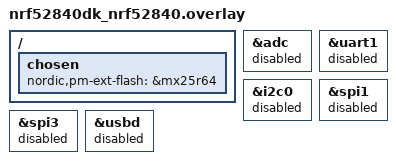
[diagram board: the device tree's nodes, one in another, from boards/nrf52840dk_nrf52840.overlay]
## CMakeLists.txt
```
#
# Copyright (c) 2024 Nordic Semiconductor ASA
#
# SPDX-License-Identifier: LicenseRef-Nordic-5-Clause
#

cmake_minimum_required(VERSION 3.20.0)

find_package(Zephyr HINTS $ENV{ZEPHYR_BASE})

project(matter-smoke-co-alarm)

# Enable GNU STD support.
include(${ZEPHYR_CONNECTEDHOMEIP_MODULE_DIR}/config/nrfconnect/app/enable-gnu-std.cmake)

# NORDIC SDK APP START

# Include all source files that are located in the Matter common directory.
include(${ZEPHYR_NRF_MODULE_DIR}/samples/matter/common/cmake/source_common.cmake)

# Include Data Model utils
include(${ZEPHYR_NRF_MODULE_DIR}/samples/matter/common/cmake/data_model.cmake)

include(${ZEPHYR_NRF_MODULE_DIR}/samples/matter/common/cmake/zap_helpers.cmake)
ncs_get_zap_parent_dir(ZAP_PARENT_DIR)

target_include_directories(app PRIVATE
    src
    ${ZAP_PARENT_DIR}
)

target_sources(app PRIVATE
    src/app_task.cpp
    src/main.cpp
    src/zcl_callbacks.cpp
)

ncs_configure_data_model()
# NORDIC SDK APP END
```

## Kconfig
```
#
# Copyright (c) 2024 Nordic Semiconductor
#
# SPDX-License-Identifier: LicenseRef-Nordic-5-Clause
#
mainmenu "Matter nRF Connect Smoke CO Alarm Example Application"

choice OPENTHREAD_NORDIC_LIBRARY_CONFIGURATION
	default OPENTHREAD_NORDIC_LIBRARY_MTD
endchoice

choice OPENTHREAD_DEVICE_TYPE
	default OPENTHREAD_MTD
endchoice

config CHIP_ENABLE_ICD_SUPPORT
	default y

config CHIP_ICD_LIT_SUPPORT
	default y

config CHIP_ICD_SIT_SLOW_POLL_LIMIT
	default 5000

config CHIP_ICD_REPORT_ON_ACTIVE_MODE
	default y

# Increase the supported event triggers due to the multiple alarm triggers
config NCS_SAMPLE_MATTER_TEST_EVENT_TRIGGERS_MAX
	default 12

# Reduce Thread TX output power to 0 dBm for SED device
config OPENTHREAD_DEFAULT_TX_POWER
	default 0

source "${ZEPHYR_CONNECTEDHOMEIP_MODULE_DIR}/config/nrfconnect/chip-module/Kconfig.features"
source "${ZEPHYR_CONNECTEDHOMEIP_MODULE_DIR}/config/nrfconnect/chip-module/Kconfig.defaults"
source "${ZEPHYR_NRF_MODULE_DIR}/samples/matter/common/src/Kconfig"
source "Kconfig.zephyr"
```

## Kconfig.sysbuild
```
#
# Copyright (c) 2024 Nordic Semiconductor ASA
#
# SPDX-License-Identifier: LicenseRef-Nordic-5-Clause
#

#### Radio core selection
config NRF_DEFAULT_IPC_RADIO
	default y

# Enable IEEE802.15.4 serialization to network core
# This config automatically pulls in the `overlay-802154.conf` in the ipc_radio image
config NETCORE_IPC_RADIO_IEEE802154
	default y if SOC_SERIES_NRF53X

# Enable Bluetooth serialization to network core
# This config automatically pulls in the `overlay-bt_hci_ipc.conf` in the ipc_radio image
config NETCORE_IPC_RADIO_BT_HCI_IPC
	default y if SOC_SERIES_NRF53X

#### Bootloader
choice BOOTLOADER
	default BOOTLOADER_MCUBOOT
endchoice

if BOOTLOADER_MCUBOOT

#### DFU multi-image support
config DFU_MULTI_IMAGE_PACKAGE_BUILD
	default y

config DFU_MULTI_IMAGE_PACKAGE_APP
	default y

config PM_EXTERNAL_FLASH_MCUBOOT_SECONDARY
	default y

#### DFU network core configuration
if SOC_SERIES_NRF53X

config MCUBOOT_UPDATEABLE_IMAGES
	default 2

choice MCUBOOT_MODE
	default MCUBOOT_MODE_OVERWRITE_ONLY
endchoice

choice BOOT_SIGNATURE_TYPE
	default BOOT_SIGNATURE_TYPE_RSA
endchoice

config SECURE_BOOT_NETCORE
	default y

config NETCORE_APP_UPDATE
	default y

config DFU_MULTI_IMAGE_PACKAGE_NET
	default y

endif # SOC_SERIES_NRF53X

if BOARD_NRF54L15DK

# Disable checking the external drivers for nRF54L15 DKs.
config PM_OVERRIDE_EXTERNAL_DRIVER_CHECK
	default y

endif # BOARD_NRF54L15DK

# Mcuboot padding size is modified to 0x1000 in pm_static file.
if SOC_NRF54L10

config PM_MCUBOOT_PAD
	default 0x1000

endif # SOC_NRF54L10

endif # BOOTLOADER_MCUBOOT

#### Enable generating factory data
config MATTER_FACTORY_DATA_GENERATE
	default y

source "share/sysbuild/Kconfig"
```

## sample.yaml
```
sample:
  description: Matter Smoke CO Alarm example
  name: Matter Smoke CO Alarm
tests:
  sample.matter.smoke_co_alarm.debug:
    sysbuild: true
    build_only: true
    integration_platforms:
      - nrf52840dk/nrf52840
      - nrf5340dk/nrf5340/cpuapp
      - nrf54l15dk/nrf54l15/cpuapp
      - nrf54l15dk/nrf54l10/cpuapp
      - nrf54lm20pdk/nrf54lm20a/cpuapp
    platform_allow:
      - nrf52840dk/nrf52840
      - nrf5340dk/nrf5340/cpuapp
      - nrf54l15dk/nrf54l15/cpuapp
      - nrf54l15dk/nrf54l10/cpuapp
      - nrf54lm20pdk/nrf54lm20a/cpuapp
    tags:
      - sysbuild
      - ci_samples_matter
  sample.matter.smoke_co_alarm.release:
    sysbuild: true
    build_only: true
    extra_args:
      - FILE_SUFFIX=release
      - SB_CONFIG_BOOTLOADER_MCUBOOT=y
      - SB_CONFIG_PARTITION_MANAGER=y
    integration_platforms:
      - nrf52840dk/nrf52840
      - nrf5340dk/nrf5340/cpuapp
      - nrf54l15dk/nrf54l15/cpuapp
      - nrf54l15dk/nrf54l10/cpuapp
      - nrf54lm20pdk/nrf54lm20a/cpuapp
    platform_allow:
      - nrf52840dk/nrf52840
      - nrf5340dk/nrf5340/cpuapp
      - nrf54l15dk/nrf54l15/cpuapp
      - nrf54l15dk/nrf54l10/cpuapp
      - nrf54lm20pdk/nrf54lm20a/cpuapp
    tags:
      - sysbuild
      - ci_samples_matter
  sample.matter.smoke_co_alarm.release.power_consumption:
    sysbuild: true
    build_only: true
    extra_args:
      - FILE_SUFFIX=release
      - smoke_co_alarm_SNIPPET=power-consumption-tests
    integration_platforms:
      - nrf52840dk/nrf52840
      - nrf5340dk/nrf5340/cpuapp
      - nrf54l15dk/nrf54l15/cpuapp
      - nrf54lm20pdk/nrf54lm20a/cpuapp
    platform_allow:
      - nrf52840dk/nrf52840
      - nrf5340dk/nrf5340/cpuapp
      - nrf54l15dk/nrf54l15/cpuapp
      - nrf54lm20pdk/nrf54lm20a/cpuapp
    tags:
      - sysbuild
      - ci_samples_matter
  sample.matter.smoke_co_alarm.debug.reference:
    sysbuild: true
    build_only: true
    integration_platforms:
      - nrf54l15dk/nrf54l15/cpuapp
    extra_args:
      - smoke_co_alarm_SNIPPET="diagnostic-logs"
    platform_allow: nrf54l15dk/nrf54l15/cpuapp
    tags:
      - sysbuild
      - ci_samples_matter
```

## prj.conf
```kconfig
#
# Copyright (c) 2024 Nordic Semiconductor ASA
#
# SPDX-License-Identifier: LicenseRef-Nordic-5-Clause
#

# Enable CHIP
CONFIG_CHIP=y
CONFIG_CHIP_PROJECT_CONFIG="src/chip_project_config.h"

# Configure ZAP file name
CONFIG_NCS_SAMPLE_MATTER_ZAP_FILE_PATH="${APPLICATION_CONFIG_DIR}/src/default_zap/smoke_co_alarm.zap"

# 32768 == 0x8000 (example Product ID added temporaly,
# as there is no assigned PID on the following list:
# https://github.com/project-chip/connectedhomeip/blob/482e6fd03196a6de45465a90003947ef4b86e0b1/docs/examples/discussion/PID_allocation_for_example_apps.md)
CONFIG_CHIP_DEVICE_PRODUCT_ID=32768
CONFIG_STD_CPP17=y

# Enable Matter pairing automatically on application start.
CONFIG_CHIP_ENABLE_PAIRING_AUTOSTART=y

# Enable Matter extended announcement and increase duration to 1 hour.
CONFIG_CHIP_BLE_EXT_ADVERTISING=y
CONFIG_CHIP_BLE_ADVERTISING_DURATION=60

# Add support for LEDs and buttons on Nordic development kits
CONFIG_DK_LIBRARY=y

# Bluetooth Low Energy configuration
CONFIG_BT_DEVICE_NAME="MatterSmoke"

# Suspend devices when the CPU goes into sleep
CONFIG_PM_DEVICE=y

# Other settings
CONFIG_THREAD_NAME=y
CONFIG_MPU_STACK_GUARD=y
CONFIG_RESET_ON_FATAL_ERROR=n
CONFIG_CHIP_LIB_SHELL=y

# Reduce application size
CONFIG_USE_SEGGER_RTT=n

# Enable Factory Data feature
CONFIG_CHIP_FACTORY_DATA=y
CONFIG_CHIP_FACTORY_DATA_BUILD=y
```

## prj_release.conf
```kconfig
#
# Copyright (c) 2024 Nordic Semiconductor ASA
#
# SPDX-License-Identifier: LicenseRef-Nordic-5-Clause
#

# Enable CHIP
CONFIG_CHIP=y
CONFIG_CHIP_PROJECT_CONFIG="src/chip_project_config.h"

# Configure ZAP file name
CONFIG_NCS_SAMPLE_MATTER_ZAP_FILE_PATH="${APPLICATION_CONFIG_DIR}/src/default_zap/smoke_co_alarm.zap"

# 32768 == 0x8000 (example Product ID added temporaly,
# as there is no assigned PID on the following list:
# https://github.com/project-chip/connectedhomeip/blob/482e6fd03196a6de45465a90003947ef4b86e0b1/docs/examples/discussion/PID_allocation_for_example_apps.md)
CONFIG_CHIP_DEVICE_PRODUCT_ID=32768
CONFIG_STD_CPP17=y

# Enable Matter pairing automatically on application start.
CONFIG_CHIP_ENABLE_PAIRING_AUTOSTART=y

# Enable Matter extended announcement and increase duration to 1 hour.
CONFIG_CHIP_BLE_EXT_ADVERTISING=y
CONFIG_CHIP_BLE_ADVERTISING_DURATION=60

# Add support for LEDs and buttons on Nordic development kits
CONFIG_DK_LIBRARY=y

# Try to disable unused RAM blocks to reduce power consumption
CONFIG_RAM_POWER_DOWN_LIBRARY=y

# Bluetooth Low Energy configuration
CONFIG_BT_DEVICE_NAME="MatterSmoke"

# Suspend devices when the CPU goes into sleep
CONFIG_PM_DEVICE=y

# Enable system reset on fatal error
CONFIG_RESET_ON_FATAL_ERROR=y

# Disable all debug features
CONFIG_USE_SEGGER_RTT=n
CONFIG_SHELL=n
CONFIG_OPENTHREAD_SHELL=n
CONFIG_CONSOLE=n
CONFIG_UART_CONSOLE=n
CONFIG_SERIAL=n
CONFIG_LOG=n
CONFIG_LOG_MODE_MINIMAL=n
CONFIG_ASSERT_VERBOSE=n
CONFIG_ASSERT_NO_FILE_INFO=y
CONFIG_PRINTK=n
CONFIG_PRINTK_SYNC=n
CONFIG_THREAD_NAME=n
CONFIG_BOOT_BANNER=n

# Enable Factory Data feature
CONFIG_CHIP_FACTORY_DATA=y
CONFIG_CHIP_FACTORY_DATA_BUILD=y

# Enable Watchdog
CONFIG_NCS_SAMPLE_MATTER_WATCHDOG=y

# Enable LTO to decrease the flash usage.
CONFIG_LTO=y
CONFIG_ISR_TABLES_LOCAL_DECLARATION=y
```

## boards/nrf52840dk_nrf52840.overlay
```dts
/*
 * Copyright (c) 2024 Nordic Semiconductor ASA
 *
 * SPDX-License-Identifier: LicenseRef-Nordic-5-Clause
 */

/ {
	chosen {
		nordic,pm-ext-flash = &mx25r64;
	};
};

/* Disable unused peripherals to reduce power consumption */
&adc {
	status = "disabled";
};
&uart1 {
	status = "disabled";
};
&i2c0 {
	status = "disabled";
};
&spi1 {
	status = "disabled";
};
&spi3 {
	status = "disabled";
};
&usbd {
	status = "disabled";
};
```

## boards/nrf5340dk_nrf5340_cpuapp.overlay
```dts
/*
 * Copyright (c) 2024 Nordic Semiconductor ASA
 *
 * SPDX-License-Identifier: LicenseRef-Nordic-5-Clause
 */

#include <zephyr/dt-bindings/ipc_service/static_vrings.h>

/ {
	chosen {
		nordic,pm-ext-flash = &mx25r64;
	};
};

/* Set IPC thread priority to the highest value to not collide with other threads. */
&ipc0 {
	zephyr,priority = <0 PRIO_COOP>;
};

/* Disable unused peripherals to reduce power consumption */
&adc {
	status = "disabled";
};
&i2c1 {
	status = "disabled";
};
&spi2 {
	status = "disabled";
};
&usbd {
	status = "disabled";
};
```

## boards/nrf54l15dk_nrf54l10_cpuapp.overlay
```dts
/*
 * Copyright (c) 2024 Nordic Semiconductor ASA
 *
 * SPDX-License-Identifier: LicenseRef-Nordic-5-Clause
 */


/ {
	chosen {
		nordic,pm-ext-flash = &mx25r64;
	};

	aliases {
		// Use watchdog wdt31 as the application watchdog
		watchdog0 = &wdt31;
	};
};

// restore full RRAM and SRAM space - by default some parts are dedicated to FLRP
&cpuapp_rram {
	reg = <0x0 DT_SIZE_K(1022)>;
};

&cpuapp_sram {
	reg = <0x20000000 DT_SIZE_K(192)>;
	ranges = <0x0 0x20000000  DT_SIZE_K(192)>;
};

// TODO: re-enable HWFC once it's fixed
&uart20 {
	/delete-property/ hw-flow-control;
};

&mx25r64 {
	status = "okay";
};

&wdt31 {
	status = "okay";
};
```

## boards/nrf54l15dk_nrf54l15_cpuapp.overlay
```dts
/*
 * Copyright (c) 2024 Nordic Semiconductor ASA
 *
 * SPDX-License-Identifier: LicenseRef-Nordic-5-Clause
 */


/ {
	chosen {
		nordic,pm-ext-flash = &mx25r64;
	};

	aliases {
		// Use watchdog wdt31 as the application watchdog
		watchdog0 = &wdt31;
	};
};

// restore full RRAM and SRAM space - by default some parts are dedicated to FLRP
&cpuapp_rram {
	reg = <0x0 DT_SIZE_K(1524)>;
};

&cpuapp_sram {
	reg = <0x20000000 DT_SIZE_K(256)>;
	ranges = <0x0 0x20000000  0x40000>;
};

// TODO: re-enable HWFC once it's fixed
&uart20 {
	/delete-property/ hw-flow-control;
};

&mx25r64 {
	status = "okay";
};

&wdt31 {
	status = "okay";
};
```

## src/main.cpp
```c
/*
 * Copyright (c) 2024 Nordic Semiconductor ASA
 *
 * SPDX-License-Identifier: LicenseRef-Nordic-5-Clause
 */

#include "app_task.h"

#include <zephyr/logging/log.h>

LOG_MODULE_REGISTER(app, CONFIG_CHIP_APP_LOG_LEVEL);

int main()
{
	CHIP_ERROR err = AppTask::Instance().StartApp();

	LOG_ERR("Exited with code %" CHIP_ERROR_FORMAT, err.Format());
	return err == CHIP_NO_ERROR ? EXIT_SUCCESS : EXIT_FAILURE;
}
```

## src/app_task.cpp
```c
/*
 * Copyright (c) 2024 Nordic Semiconductor ASA
 *
 * SPDX-License-Identifier: LicenseRef-Nordic-5-Clause
 */

#include "app_task.h"

#include "app/matter_init.h"
#include "app/task_executor.h"
#include "board/board.h"
#include "lib/core/CHIPError.h"
#include "lib/support/CodeUtils.h"

#include <app-common/zap-generated/attributes/Accessors.h>
#include <app/clusters/identify-server/identify-server.h>
#include <app/clusters/smoke-co-alarm-server/SmokeCOTestEventTriggerHandler.h>
#include <app/clusters/smoke-co-alarm-server/smoke-co-alarm-server.h>
#include <setup_payload/OnboardingCodesUtil.h>

#include <zephyr/logging/log.h>

LOG_MODULE_DECLARE(app, CONFIG_CHIP_APP_LOG_LEVEL);

using namespace ::chip;
using namespace ::chip::app;
using namespace ::chip::DeviceLayer;

namespace
{

constexpr uint32_t kExpressedStateLedEvenBlinkMs = 300;
constexpr uint32_t kExpressedStateLedOddBlink1Ms = 300;
constexpr uint32_t kExpressedStateLedOddBlink2Ms = 700;
constexpr uint32_t kSelfTestDurationMs = 5000;
constexpr uint32_t kSelfTestLedUpdateTimeMs = 200;

static std::array<Clusters::SmokeCoAlarm::ExpressedStateEnum, SmokeCoAlarmServer::kPriorityOrderLength>
	sPriorityOrder = { Clusters::SmokeCoAlarm::ExpressedStateEnum::kSmokeAlarm,
			   Clusters::SmokeCoAlarm::ExpressedStateEnum::kCOAlarm,
			   Clusters::SmokeCoAlarm::ExpressedStateEnum::kHardwareFault,
			   Clusters::SmokeCoAlarm::ExpressedStateEnum::kTesting,
			   Clusters::SmokeCoAlarm::ExpressedStateEnum::kEndOfService,
			   Clusters::SmokeCoAlarm::ExpressedStateEnum::kBatteryAlert,
			   Clusters::SmokeCoAlarm::ExpressedStateEnum::kInterconnectSmoke,
			   Clusters::SmokeCoAlarm::ExpressedStateEnum::kInterconnectCO };

Identify sIdentify = { AppTask::Instance().kSmokeCoAlarmEndpointId, AppTask::IdentifyStartHandler,
		       AppTask::IdentifyStopHandler, Clusters::Identify::IdentifyTypeEnum::kVisibleIndicator };

#ifdef CONFIG_CHIP_ICD_UAT_SUPPORT
#define UAT_BUTTON_MASK DK_BTN3_MSK
#endif
} /* namespace */

void AppTask::IdentifyStartHandler(Identify *)
{
	Nrf::PostTask(
		[] { Nrf::GetBoard().GetLED(Nrf::DeviceLeds::LED2).Blink(Nrf::LedConsts::kIdentifyBlinkRate_ms); });
}

void AppTask::IdentifyStopHandler(Identify *)
{
	Nrf::PostTask([] { Nrf::GetBoard().GetLED(Nrf::DeviceLeds::LED2).Set(false); });
}

void AppTask::ButtonEventHandler(Nrf::ButtonState state, Nrf::ButtonMask hasChanged)
{
#ifdef CONFIG_CHIP_ICD_UAT_SUPPORT
	if ((UAT_BUTTON_MASK & state & hasChanged)) {
		LOG_INF("ICD UserActiveMode has been triggered.");
		Server::GetInstance().GetICDManager().OnNetworkActivity();
	}
#endif
}

void AppTask::UpdatedExpressedLedState()
{
	Clusters::SmokeCoAlarm::ExpressedStateEnum state;
	SmokeCoAlarmServer::Instance().GetExpressedState(kSmokeCoAlarmEndpointId, state);

	if (mCurrentState == state) {
		return;
	}
	mCurrentState = state;

	k_timer_stop(&mSelfTestLedTimer);

	switch (state) {
	case Clusters::SmokeCoAlarm::ExpressedStateEnum::kNormal:
		Nrf::GetBoard().GetLED(Nrf::DeviceLeds::LED2).Set(false);
		Nrf::GetBoard().GetLED(Nrf::DeviceLeds::LED3).Set(false);
		Nrf::GetBoard().GetLED(Nrf::DeviceLeds::LED4).Set(false);
		break;
	case Clusters::SmokeCoAlarm::ExpressedStateEnum::kSmokeAlarm:
		Nrf::GetBoard().GetLED(Nrf::DeviceLeds::LED2).Blink(kExpressedStateLedEvenBlinkMs);
		Nrf::GetBoard().GetLED(Nrf::DeviceLeds::LED3).Set(false);
		Nrf::GetBoard().GetLED(Nrf::DeviceLeds::LED4).Set(false);
		break;
	case Clusters::SmokeCoAlarm::ExpressedStateEnum::kCOAlarm:
		Nrf::GetBoard().GetLED(Nrf::DeviceLeds::LED2).Set(false);
		Nrf::GetBoard().GetLED(Nrf::DeviceLeds::LED3).Blink(kExpressedStateLedEvenBlinkMs);
		Nrf::GetBoard().GetLED(Nrf::DeviceLeds::LED4).Set(false);
		break;
	case Clusters::SmokeCoAlarm::ExpressedStateEnum::kBatteryAlert:
		Nrf::GetBoard().GetLED(Nrf::DeviceLeds::LED2).Set(false);
		Nrf::GetBoard().GetLED(Nrf::DeviceLeds::LED3).Set(false);
		Nrf::GetBoard().GetLED(Nrf::DeviceLeds::LED4).Blink(kExpressedStateLedEvenBlinkMs);
		break;
	case Clusters::SmokeCoAlarm::ExpressedStateEnum::kTesting:
		Nrf::GetBoard().GetLED(Nrf::DeviceLeds::LED2).Set(false);
		Nrf::GetBoard().GetLED(Nrf::DeviceLeds::LED3).Set(false);
		Nrf::GetBoard().GetLED(Nrf::DeviceLeds::LED4).Set(false);

		k_timer_start(&mSelfTestLedTimer, K_MSEC(kSelfTestLedUpdateTimeMs), K_NO_WAIT);
		Nrf::GetBoard().GetLED(Nrf::DeviceLeds::LED2).Set(true);

		break;
	case Clusters::SmokeCoAlarm::ExpressedStateEnum::kHardwareFault:
		Nrf::GetBoard().GetLED(Nrf::DeviceLeds::LED2).Set(false);
		Nrf::GetBoard().GetLED(Nrf::DeviceLeds::LED3).Set(false);
		Nrf::GetBoard().GetLED(Nrf::DeviceLeds::LED4).Set(false);

		Nrf::GetBoard()
			.GetLED(Nrf::DeviceLeds::LED2)
			.Blink(kExpressedStateLedOddBlink1Ms, kExpressedStateLedOddBlink2Ms);
		Nrf::GetBoard()
			.GetLED(Nrf::DeviceLeds::LED3)
			.Blink(kExpressedStateLedOddBlink1Ms, kExpressedStateLedOddBlink2Ms);
		Nrf::GetBoard()
			.GetLED(Nrf::DeviceLeds::LED4)
			.Blink(kExpressedStateLedOddBlink1Ms, kExpressedStateLedOddBlink2Ms);
		break;
	case Clusters::SmokeCoAlarm::ExpressedStateEnum::kEndOfService:
		Nrf::GetBoard().GetLED(Nrf::DeviceLeds::LED2).Set(false);
		Nrf::GetBoard().GetLED(Nrf::DeviceLeds::LED3).Set(false);
		Nrf::GetBoard().GetLED(Nrf::DeviceLeds::LED4).Set(false);

		Nrf::GetBoard()
			.GetLED(Nrf::DeviceLeds::LED2)
			.Blink(kExpressedStateLedOddBlink2Ms, kExpressedStateLedOddBlink1Ms);
		Nrf::GetBoard()
			.GetLED(Nrf::DeviceLeds::LED3)
			.Blink(kExpressedStateLedOddBlink2Ms, kExpressedStateLedOddBlink1Ms);
		Nrf::GetBoard()
			.GetLED(Nrf::DeviceLeds::LED4)
			.Blink(kExpressedStateLedOddBlink2Ms, kExpressedStateLedOddBlink1Ms);
		break;
	case Clusters::SmokeCoAlarm::ExpressedStateEnum::kInterconnectSmoke:
	case Clusters::SmokeCoAlarm::ExpressedStateEnum::kInterconnectCO:
	case Clusters::SmokeCoAlarm::ExpressedStateEnum::kUnknownEnumValue:
	default:
		break;
	}
}

bool HandleSmokeCOTestEventTrigger(uint64_t eventTrigger)
{
	SmokeCOTrigger trigger = static_cast<SmokeCOTrigger>(eventTrigger);

	switch (trigger) {
	case SmokeCOTrigger::kForceSmokeCritical:
		LOG_INF("Triggered smoke alarm with critical severity");
		VerifyOrReturnValue(
			SmokeCoAlarmServer::Instance().SetSmokeState(AppTask::Instance().kSmokeCoAlarmEndpointId,
								     Clusters::SmokeCoAlarm::AlarmStateEnum::kCritical),
			false);
		SmokeCoAlarmServer::Instance().SetExpressedStateByPriority(AppTask::Instance().kSmokeCoAlarmEndpointId,
									   sPriorityOrder);
		break;
	case SmokeCOTrigger::kForceCOCritical:
		LOG_INF("Triggered CO alarm with critical severity");
		VerifyOrReturnValue(
			SmokeCoAlarmServer::Instance().SetCOState(AppTask::Instance().kSmokeCoAlarmEndpointId,
								  Clusters::SmokeCoAlarm::AlarmStateEnum::kCritical),
			false);
		SmokeCoAlarmServer::Instance().SetExpressedStateByPriority(AppTask::Instance().kSmokeCoAlarmEndpointId,
									   sPriorityOrder);
		break;
	case SmokeCOTrigger::kForceMalfunction:
		LOG_INF("Triggered hardware fault alert");
		VerifyOrReturnValue(SmokeCoAlarmServer::Instance().SetHardwareFaultAlert(
					    AppTask::Instance().kSmokeCoAlarmEndpointId, true),
				    false);
		SmokeCoAlarmServer::Instance().SetExpressedStateByPriority(AppTask::Instance().kSmokeCoAlarmEndpointId,
									   sPriorityOrder);
		break;
	case SmokeCOTrigger::kForceLowBatteryCritical:
		LOG_INF("Triggered low battery alert with critical severity");
		VerifyOrReturnValue(SmokeCoAlarmServer::Instance().SetBatteryAlert(
					    AppTask::Instance().kSmokeCoAlarmEndpointId,
					    Clusters::SmokeCoAlarm::AlarmStateEnum::kCritical),
				    false);
		SmokeCoAlarmServer::Instance().SetExpressedStateByPriority(AppTask::Instance().kSmokeCoAlarmEndpointId,
									   sPriorityOrder);
		break;
	case SmokeCOTrigger::kForceEndOfLife:
		LOG_INF("Triggered end of service alert");
		VerifyOrReturnValue(SmokeCoAlarmServer::Instance().SetEndOfServiceAlert(
					    AppTask::Instance().kSmokeCoAlarmEndpointId,
					    Clusters::SmokeCoAlarm::EndOfServiceEnum::kExpired),
				    false);
		SmokeCoAlarmServer::Instance().SetExpressedStateByPriority(AppTask::Instance().kSmokeCoAlarmEndpointId,
									   sPriorityOrder);
		break;
	case SmokeCOTrigger::kClearSmoke:
		LOG_INF("Triggered end of smoke alarm action");
		VerifyOrReturnValue(
			SmokeCoAlarmServer::Instance().SetSmokeState(AppTask::Instance().kSmokeCoAlarmEndpointId,
								     Clusters::SmokeCoAlarm::AlarmStateEnum::kNormal),
			false);
		SmokeCoAlarmServer::Instance().SetExpressedStateByPriority(AppTask::Instance().kSmokeCoAlarmEndpointId,
									   sPriorityOrder);
		break;
	case SmokeCOTrigger::kClearCO:
		LOG_INF("Triggered end of CO alarm action");
		VerifyOrReturnValue(
			SmokeCoAlarmServer::Instance().SetCOState(AppTask::Instance().kSmokeCoAlarmEndpointId,
								  Clusters::SmokeCoAlarm::AlarmStateEnum::kNormal),
			false);
		SmokeCoAlarmServer::Instance().SetExpressedStateByPriority(AppTask::Instance().kSmokeCoAlarmEndpointId,
									   sPriorityOrder);
		break;
	case SmokeCOTrigger::kClearMalfunction:
		LOG_INF("Triggered end of hardware fault alert action");
		VerifyOrReturnValue(SmokeCoAlarmServer::Instance().SetHardwareFaultAlert(
					    AppTask::Instance().kSmokeCoAlarmEndpointId, false),
				    false);
		SmokeCoAlarmServer::Instance().SetExpressedStateByPriority(AppTask::Instance().kSmokeCoAlarmEndpointId,
									   sPriorityOrder);
		break;
	case SmokeCOTrigger::kClearEndOfLife:
		LOG_INF("Triggered end of end of service alert action");
		VerifyOrReturnValue(SmokeCoAlarmServer::Instance().SetEndOfServiceAlert(
					    AppTask::Instance().kSmokeCoAlarmEndpointId,
					    Clusters::SmokeCoAlarm::EndOfServiceEnum::kNormal),
				    false);
		SmokeCoAlarmServer::Instance().SetExpressedStateByPriority(AppTask::Instance().kSmokeCoAlarmEndpointId,
									   sPriorityOrder);
		break;
	case SmokeCOTrigger::kClearBatteryLevelLow:
		LOG_INF("Triggered end of low battery level alert action");
		VerifyOrReturnValue(
			SmokeCoAlarmServer::Instance().SetBatteryAlert(AppTask::Instance().kSmokeCoAlarmEndpointId,
								       Clusters::SmokeCoAlarm::AlarmStateEnum::kNormal),
			false);
		SmokeCoAlarmServer::Instance().SetExpressedStateByPriority(AppTask::Instance().kSmokeCoAlarmEndpointId,
									   sPriorityOrder);
		break;
	case SmokeCOTrigger::kForceSmokeWarning:
		LOG_WRN("Triggered unsupported smoke alarm with warning severity");
		return false;
	case SmokeCOTrigger::kForceSmokeInterconnect:
		LOG_WRN("Triggered unsupported smoke interconnect alarm");
		return false;
	case SmokeCOTrigger::kForceCOWarning:
		LOG_WRN("Triggered unsupported CO alarm with warning severity");
		return false;
	case SmokeCOTrigger::kForceCOInterconnect:
		LOG_WRN("Triggered unsupported CO interconnect alarm");
		return false;
	case SmokeCOTrigger::kForceSmokeContaminationHigh:
		LOG_WRN("Triggered unsupported high smoke contamination alarm");
		return false;
	case SmokeCOTrigger::kForceSmokeContaminationLow:
		LOG_WRN("Triggered unsupported low smoke contamination alarm");
		return false;
	case SmokeCOTrigger::kForceSmokeSensitivityHigh:
		LOG_WRN("Triggered unsupported high smoke sensitivity alarm");
		return false;
	case SmokeCOTrigger::kForceSmokeSensitivityLow:
		LOG_WRN("Triggered unsupported low smoke sensitivity alarm");
		return false;
	case SmokeCOTrigger::kForceLowBatteryWarning:
		LOG_WRN("Triggered unsupported low battery alert with warning severity");
		return false;
	case SmokeCOTrigger::kForceSilence:
		LOG_WRN("Triggered unsupported alarm mute action");
		return false;
	case SmokeCOTrigger::kClearSmokeInterconnect:
		LOG_WRN("Triggered unsupported end of smoke interconnect alarm action");
		return false;
	case SmokeCOTrigger::kClearCOInterconnect:
		LOG_WRN("Triggered unsupported end of CO interconnect alarm action");
		return false;
	case SmokeCOTrigger::kClearSilence:
		LOG_WRN("Triggered unsupported unmute action");
		return false;
	case SmokeCOTrigger::kClearContamination:
		LOG_WRN("Triggered unsupported end of smoke contamination alert action");
		return false;
	case SmokeCOTrigger::kClearSensitivity:
		LOG_WRN("Triggered unsupported end of smoke sensitivity alert action");
		return false;
	default:
		return false;
	}

	AppTask::Instance().UpdatedExpressedLedState();

	return true;
}

void AppTask::SelfTestTimerTimeoutCallback(k_timer *timer)
{
	Nrf::PostTask([] { EndSelfTestEventHandler(); });
}

void AppTask::EndSelfTestEventHandler()
{
	LOG_INF("Alarm self test action end");
	SmokeCoAlarmServer::Instance().SetTestInProgress(kSmokeCoAlarmEndpointId, false);
	SmokeCoAlarmServer::Instance().SetExpressedStateByPriority(kSmokeCoAlarmEndpointId, sPriorityOrder);
	Instance().UpdatedExpressedLedState();
}

void AppTask::SelfTestLedTimerTimeoutCallback(k_timer *timer)
{
	Nrf::PostTask([] { SelfTestLedTimerEventHandler(); });
}

void AppTask::SelfTestLedTimerEventHandler()
{
	if (Nrf::GetBoard().GetLED(Nrf::DeviceLeds::LED2).GetState()) {
		Nrf::GetBoard().GetLED(Nrf::DeviceLeds::LED2).Set(false);
		Nrf::GetBoard().GetLED(Nrf::DeviceLeds::LED3).Set(true);
	} else if (Nrf::GetBoard().GetLED(Nrf::DeviceLeds::LED3).GetState()) {
		Nrf::GetBoard().GetLED(Nrf::DeviceLeds::LED3).Set(false);
		Nrf::GetBoard().GetLED(Nrf::DeviceLeds::LED4).Set(true);
	} else if (Nrf::GetBoard().GetLED(Nrf::DeviceLeds::LED4).GetState()) {
		Nrf::GetBoard().GetLED(Nrf::DeviceLeds::LED4).Set(false);
		Nrf::GetBoard().GetLED(Nrf::DeviceLeds::LED2).Set(true);
	}

	k_timer_start(&Instance().mSelfTestLedTimer, K_MSEC(kSelfTestLedUpdateTimeMs), K_NO_WAIT);
}

#ifdef CONFIG_NCS_SAMPLE_MATTER_TEST_EVENT_TRIGGERS
CHIP_ERROR AppTask::PowerSourceOnEventCallback(Nrf::Matter::TestEventTrigger::TriggerValue endpointId)
{
	if (endpointId == kWiredPowerSourceEndpointId || endpointId == kBatteryPowerSourceEndpointId) {
		LOG_INF("Event Trigger: Power Source on endpoint id %d activated.", endpointId);
	} else {
		LOG_ERR("Event Trigger: Power Source On triggered on invalid endpoint id %d", endpointId);
		return CHIP_ERROR_INVALID_ARGUMENT;
	}

	/* Wired power source is treated as primary one. */
	if (endpointId == kWiredPowerSourceEndpointId) {
		Clusters::PowerSource::Attributes::Status::Set(kWiredPowerSourceEndpointId,
							       Clusters::PowerSource::PowerSourceStatusEnum::kActive);

		Clusters::PowerSource::PowerSourceStatusEnum status;
		Clusters::PowerSource::Attributes::Status::Get(kBatteryPowerSourceEndpointId, &status);

		/* If battery power source was active, change its state to standby. */
		if (status == Clusters::PowerSource::PowerSourceStatusEnum::kActive) {
			Clusters::PowerSource::Attributes::Status::Set(
				kBatteryPowerSourceEndpointId, Clusters::PowerSource::PowerSourceStatusEnum::kStandby);
		}
	} else {
		Clusters::PowerSource::PowerSourceStatusEnum status;
		Clusters::PowerSource::Attributes::Status::Get(kWiredPowerSourceEndpointId, &status);

		/* If wired power source is active, change put requested power source into standby state to standby. */
		if (status == Clusters::PowerSource::PowerSourceStatusEnum::kActive) {
			Clusters::PowerSource::Attributes::Status::Set(
				kBatteryPowerSourceEndpointId, Clusters::PowerSource::PowerSourceStatusEnum::kStandby);
		} else {
			Clusters::PowerSource::Attributes::Status::Set(
				kBatteryPowerSourceEndpointId, Clusters::PowerSource::PowerSourceStatusEnum::kActive);
		}
	}

	return CHIP_NO_ERROR;
}

CHIP_ERROR AppTask::PowerSourceOffEventCallback(Nrf::Matter::TestEventTrigger::TriggerValue endpointId)
{
	if (endpointId == kWiredPowerSourceEndpointId || endpointId == kBatteryPowerSourceEndpointId) {
		LOG_INF("Event Trigger: Power Source on endpoint id %d deactivated.", endpointId);
	} else {
		LOG_ERR("Event Trigger: Power Source Off triggered on invalid endpoint id %d", endpointId);
		return CHIP_ERROR_INVALID_ARGUMENT;
	}

	/* Wired power source is treated as primary one. */
	if (endpointId == kWiredPowerSourceEndpointId) {
		Clusters::PowerSource::Attributes::Status::Set(
			kWiredPowerSourceEndpointId, Clusters::PowerSource::PowerSourceStatusEnum::kUnavailable);

		Clusters::PowerSource::PowerSourceStatusEnum status;
		Clusters::PowerSource::Attributes::Status::Get(kBatteryPowerSourceEndpointId, &status);

		/* If battery power source was standby, change its state to active. */
		if (status == Clusters::PowerSource::PowerSourceStatusEnum::kStandby) {
			Clusters::PowerSource::Attributes::Status::Set(
				kBatteryPowerSourceEndpointId, Clusters::PowerSource::PowerSourceStatusEnum::kActive);
		}
	} else {
		Clusters::PowerSource::Attributes::Status::Set(
			kBatteryPowerSourceEndpointId, Clusters::PowerSource::PowerSourceStatusEnum::kUnavailable);
	}

	return CHIP_NO_ERROR;
}
#endif

CHIP_ERROR AppTask::Init()
{
	/* Initialize Matter stack */
	ReturnErrorOnFailure(Nrf::Matter::PrepareServer());

	if (!Nrf::GetBoard().Init(ButtonEventHandler)) {
		LOG_ERR("User interface initialization failed.");
		return CHIP_ERROR_INCORRECT_STATE;
	}

	k_timer_init(&mSelfTestLedTimer, &SelfTestLedTimerTimeoutCallback, nullptr);
	k_timer_init(&mSelfTestTimer, &SelfTestTimerTimeoutCallback, nullptr);

	/* Register Matter event handler that controls the connectivity status LED based on the captured Matter network
	 * state. */
	ReturnErrorOnFailure(Nrf::Matter::RegisterEventHandler(Nrf::Board::DefaultMatterEventHandler, 0));

	/* Register Smoke CO Alarm test event triggers */
#ifdef CONFIG_NCS_SAMPLE_MATTER_TEST_EVENT_TRIGGERS
	/* Register Smoke CO alarm test events handler */
	static chip::SmokeCOTestEventTriggerHandler sSmokeCoAlarmTestEventTrigger;
	ReturnErrorOnFailure(Nrf::Matter::TestEventTrigger::Instance().RegisterTestEventTriggerHandler(
		&sSmokeCoAlarmTestEventTrigger));

	/* Register test event handler to change the power source. */
	ReturnErrorOnFailure(Nrf::Matter::TestEventTrigger::Instance().RegisterTestEventTrigger(
		kPowerSourceOnEventTriggerId,
		Nrf::Matter::TestEventTrigger::EventTrigger{ 0xFFFF, PowerSourceOnEventCallback }));
	ReturnErrorOnFailure(Nrf::Matter::TestEventTrigger::Instance().RegisterTestEventTrigger(
		kPowerSourceOffEventTriggerId,
		Nrf::Matter::TestEventTrigger::EventTrigger{ 0xFFFF, PowerSourceOffEventCallback }));
#endif

	return Nrf::Matter::StartServer();
}

CHIP_ERROR AppTask::StartApp()
{
	ReturnErrorOnFailure(Init());

	while (true) {
		Nrf::DispatchNextTask();
	}

	return CHIP_NO_ERROR;
}

void AppTask::SelfTestHandler()
{
	LOG_INF("Triggered alarm self test action");
	k_timer_start(&Instance().mSelfTestTimer, K_MSEC(kSelfTestDurationMs), K_NO_WAIT);
	UpdatedExpressedLedState();
}
```

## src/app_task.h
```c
/*
 * Copyright (c) 2024 Nordic Semiconductor ASA
 *
 * SPDX-License-Identifier: LicenseRef-Nordic-5-Clause
 */

#pragma once

#include "board/board.h"

#include <platform/CHIPDeviceLayer.h>

#ifdef CONFIG_NCS_SAMPLE_MATTER_TEST_EVENT_TRIGGERS
#include "event_triggers/event_triggers.h"
#endif

struct k_timer;
struct Identify;

class AppTask {
public:
	static AppTask &Instance()
	{
		static AppTask sAppTask;
		return sAppTask;
	};

	CHIP_ERROR StartApp();
	static void IdentifyStartHandler(Identify *);
	static void IdentifyStopHandler(Identify *);

	void UpdatedExpressedLedState();
	void SelfTestHandler();

	static constexpr chip::EndpointId kSmokeCoAlarmEndpointId = 1;
	static constexpr chip::EndpointId kWiredPowerSourceEndpointId = 0;
	static constexpr chip::EndpointId kBatteryPowerSourceEndpointId = 1;

private:
	CHIP_ERROR Init();

	static void ButtonEventHandler(Nrf::ButtonState state, Nrf::ButtonMask hasChanged);
	static void SelfTestLedTimerTimeoutCallback(k_timer *timer);
	static void SelfTestLedTimerEventHandler();
	static void SelfTestTimerTimeoutCallback(k_timer *timer);
	static void EndSelfTestEventHandler();

#ifdef CONFIG_NCS_SAMPLE_MATTER_TEST_EVENT_TRIGGERS
	constexpr static Nrf::Matter::TestEventTrigger::EventTriggerId kPowerSourceOnEventTriggerId = 0xFFFF'FFFF'8000'0000;
	constexpr static Nrf::Matter::TestEventTrigger::EventTriggerId kPowerSourceOffEventTriggerId = 0xFFFF'FFFF'8001'0000;
	static CHIP_ERROR PowerSourceOnEventCallback(Nrf::Matter::TestEventTrigger::TriggerValue);
	static CHIP_ERROR PowerSourceOffEventCallback(Nrf::Matter::TestEventTrigger::TriggerValue);
#endif

	k_timer mSelfTestLedTimer;
	k_timer mSelfTestTimer;
	chip::app::Clusters::SmokeCoAlarm::ExpressedStateEnum mCurrentState;
};
```

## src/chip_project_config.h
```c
/*
 * Copyright (c) 2024 Nordic Semiconductor ASA
 *
 * SPDX-License-Identifier: LicenseRef-Nordic-5-Clause
 */

/**
 *    @file
 *          Example project configuration file for CHIP.
 *
 *          This is a place to put application or project-specific overrides
 *          to the default configuration values for general CHIP features.
 *
 */

#pragma once
```

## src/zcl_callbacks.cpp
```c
/*
 * Copyright (c) 2024 Nordic Semiconductor ASA
 *
 * SPDX-License-Identifier: LicenseRef-Nordic-5-Clause
 */

#include "app_task.h"

#include <app/icd/server/ICDConfigurationData.h>

#include <app-common/zap-generated/attributes/Accessors.h>
#include <app-common/zap-generated/ids/Attributes.h>
#include <app-common/zap-generated/ids/Clusters.h>
#include <app/ConcreteAttributePath.h>

#ifdef CONFIG_CHIP_ICD_DSLS_SUPPORT
#include <app/icd/server/ICDNotifier.h>
#endif

#include <lib/support/logging/CHIPLogging.h>

using namespace ::chip;
using namespace ::chip::app;
using namespace ::chip::app::Clusters;

#ifdef CONFIG_CHIP_ICD_DSLS_SUPPORT
void MatterPostAttributeChangeCallback(const chip::app::ConcreteAttributePath &attributePath, uint8_t type,
				       uint16_t size, uint8_t *value)
{
	ClusterId clusterId = attributePath.mClusterId;
	AttributeId attributeId = attributePath.mAttributeId;
	EndpointId endpointId = attributePath.mEndpointId;

	ChipLogProgress(Zcl, "Cluster callback: " ChipLogFormatMEI, ChipLogValueMEI(clusterId));

	if (clusterId == PowerSource::Id && attributeId == PowerSource::Attributes::Status::Id) {
		PowerSource::PowerSourceStatusEnum state =
			*(reinterpret_cast<PowerSource::PowerSourceStatusEnum *>(value));

		/* We do not care about the battery source changes, as it's wired source that dictates the ordering. */
		if (endpointId != AppTask::Instance().kWiredPowerSourceEndpointId) {
			return;
		}

		if (state == PowerSource::PowerSourceStatusEnum::kActive) {
			/* Wired source is active, we can switch into the SIT mode. */
			chip::DeviceLayer::PlatformMgr().ScheduleWork(
				[](intptr_t arg) {
					chip::app::ICDNotifier::GetInstance().NotifySITModeRequestNotification();
				},
				0);
			ChipLogProgress(Zcl, "Wired power source was activated, moving into the ICD SIT mode.");
		} else {
			/* Wired source is inactive, so we need to change mode into LIT to save power. */
			chip::DeviceLayer::PlatformMgr().ScheduleWork(
				[](intptr_t arg) {
					chip::app::ICDNotifier::GetInstance().NotifySITModeRequestWithdrawal();
				},
				0);
			ChipLogProgress(Zcl, "Wired power source was deactivated, moving into the ICD LIT mode.");
		}
	}
}

void emberAfPowerSourceClusterInitCallback(EndpointId endpoint)
{
	Clusters::PowerSource::PowerSourceStatusEnum wiredPowerSourceState;
	Clusters::PowerSource::Attributes::Status::Get(AppTask::Instance().kWiredPowerSourceEndpointId, &wiredPowerSourceState);

	if (wiredPowerSourceState == Clusters::PowerSource::PowerSourceStatusEnum::kActive) {
		/* Request switching to SIT, as soon as it's possible. */
		chip::DeviceLayer::PlatformMgr().ScheduleWork(
			[](intptr_t arg) { chip::app::ICDNotifier::GetInstance().NotifySITModeRequestNotification(); },
			0);
	}
}
#endif /* CONFIG_CHIP_ICD_DSLS_SUPPORT */

void emberAfPluginSmokeCoAlarmSelfTestRequestCommand(EndpointId endpointId)
{
	if (endpointId == AppTask::Instance().kSmokeCoAlarmEndpointId) {
		AppTask::Instance().SelfTestHandler();
	}
}
```
